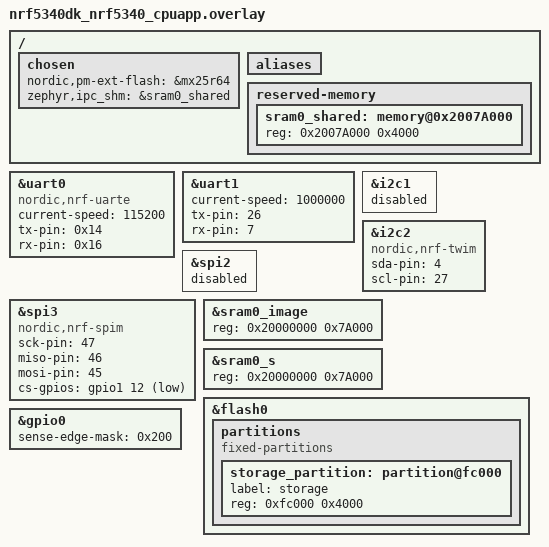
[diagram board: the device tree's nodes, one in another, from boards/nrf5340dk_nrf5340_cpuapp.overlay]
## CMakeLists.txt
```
# SPDX-License-Identifier: Apache-2.0

cmake_minimum_required(VERSION 3.13.1)

find_package(Zephyr REQUIRED HINTS $ENV{ZEPHYR_BASE})
project(comprensive_example)

# NORDIC SDK APP START

target_sources(app PRIVATE src/main.c)

target_sources_ifdef(CONFIG_EXAMPLE_I2C app
                     PRIVATE src/iic_thread.c)
					 
target_sources_ifdef(CONFIG_EXAMPLE_SPIM app
                     PRIVATE src/spi_thread.c)
					 
target_sources_ifdef(CONFIG_EXAMPLE_HS_UART app
                     PRIVATE src/uart_thread.c)
					 
target_sources_ifdef(CONFIG_EXAMPLE_ADC app
                     PRIVATE src/adc_thread.c)
					 
target_sources_ifdef(CONFIG_RPC_REMOTE_API app
                     PRIVATE src/rpc_app_api_general.c src/rpc_app_api.c src/rpc_thread.c)				 

target_sources_ifdef(CONFIG_RPC_SMP_BT app
                     PRIVATE src/rpc_app_smp_bt.c)
					 
target_sources_ifdef(CONFIG_EXAMPLE_FLASH app
                     PRIVATE src/flash_thread.c)

zephyr_library_include_directories(.)

# NORDIC SDK APP END
```

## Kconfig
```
#
# Copyright (c) 2018 Nordic Semiconductor ASA
#
# SPDX-License-Identifier: LicenseRef-BSD-5-Clause-Nordic
#

source "Kconfig.zephyr"
menu "comprehensive_rpc example"

config BLE_NETWORK_CORE
	bool "Both BLE host and controller run on network core"
	help
	  Enable the whole BLE stack running on network core

config EXAMPLE_I2C
	bool "load I2C example or not"
	help
		if yes, load I2C example
		
config EXAMPLE_SPIM
	bool "load SPI master example or not"
	help
		if yes, load SPI master example		
		
config EXAMPLE_EXT_INT
	bool "load external IO interrupt example or not"
	help
		if yes, load external IO interrupt example

config EXAMPLE_ADC
	bool "load ADC example or not"
	help
		if yes, load ADC example		

config EXAMPLE_HS_UART
	bool "load high speed UART example or not"
	help
		if yes, load high speed UART example	  

config EXAMPLE_FLASH
	bool "load Flash access usage example"
	default n
	help
		if yes, load Flash access usage example

config RPC_REMOTE_API
	bool "app core and net core communicate by remote API. that is, app core can call net core API, and net core can also call app core API"
	help
	  enable the RPC api mode
	  
config RPC_SMP_BT
	bool "load DFU example over BLE SMP"
	help
		if yes, load DFU example over BLE SMP		
		
module = COMPREHENSIVE_RPC_EXAMPLE_CONFIG
module-str = comprehensive_rpc example configurations
source "${ZEPHYR_BASE}/subsys/logging/Kconfig.template.log_config"

endmenu
```

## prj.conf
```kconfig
CONFIG_NFCT_PINS_AS_GPIOS=y

## thread monitor ##
CONFIG_THREAD_ANALYZER=y
CONFIG_THREAD_NAME=y

## logging configurations ##
CONFIG_ASSERT=y
CONFIG_LOG=y
CONFIG_LOG_PRINTK=y
CONFIG_LOG_BUFFER_SIZE=8192

## Change logging backend to RTT ##
# CONFIG_LOG_BACKEND_UART=n
# CONFIG_LOG_BACKEND_RTT=y
# CONFIG_USE_SEGGER_RTT=y
# CONFIG_RTT_CONSOLE=y
# CONFIG_UART_CONSOLE=n

## peripherals ##
CONFIG_GPIO=y
CONFIG_DK_LIBRARY=y

## stack size configurations ##
CONFIG_SYSTEM_WORKQUEUE_STACK_SIZE=4096
# CONFIG_ISR_STACK_SIZE=2048
CONFIG_HEAP_MEM_POOL_SIZE=12288
CONFIG_MAIN_STACK_SIZE=2048

## I2C master example ##
CONFIG_EXAMPLE_I2C=y
CONFIG_I2C=y
CONFIG_NRFX_TWIM2=y

## external interrupt example (in IIC thread) ##
CONFIG_EXAMPLE_EXT_INT=y

## high speed uart example ##
CONFIG_EXAMPLE_HS_UART=y
CONFIG_SERIAL=y
CONFIG_UART_ASYNC_API=y
CONFIG_UART_1_ASYNC=y
CONFIG_NRFX_UARTE1=y
CONFIG_UART_1_NRF_HW_ASYNC=y
CONFIG_UART_1_NRF_HW_ASYNC_TIMER=1

## SPI master example ##
CONFIG_EXAMPLE_SPIM=y
CONFIG_SPI=y
CONFIG_NRFX_SPIM3=y

## Load ADC example ##
CONFIG_EXAMPLE_ADC=y
CONFIG_ADC=y
CONFIG_ADC_ASYNC=y
CONFIG_ADC_NRFX_SAADC=y

## Flash access usage example ##
CONFIG_EXAMPLE_FLASH=y
CONFIG_FLASH=y
CONFIG_FLASH_PAGE_LAYOUT=y
CONFIG_FLASH_MAP=y
CONFIG_NVS=y
CONFIG_MPU_ALLOW_FLASH_WRITE=y
CONFIG_SETTINGS=y

## Device power management example ##
CONFIG_PM_DEVICE=y

## RPC example configurations ##
CONFIG_RPC_REMOTE_API=y
CONFIG_NRF_RPC=y
CONFIG_NRF_RPC_CBOR=y
CONFIG_NRF_RPC_THREAD_STACK_SIZE=4096

## Common DFU settings ##
CONFIG_BLE_NETWORK_CORE=y
CONFIG_NRF53_UPGRADE_NETWORK_CORE=y
CONFIG_BOOTLOADER_MCUBOOT=y
CONFIG_BOARD_ENABLE_CPUNET=y

## Open the following configs to run nrf_dfu ##
# CONFIG_NRF_DFU=y
# CONFIG_NRF_DFU_RPC_APP=y
# CONFIG_NRF_DFU_LOG_LEVEL=3
# CONFIG_IMG_MANAGER=y
# CONFIG_MCUBOOT_IMG_MANAGER=y
# CONFIG_IMG_BLOCK_BUF_SIZE=4096

## secondary slot on external Flash ##
CONFIG_PM_PARTITION_SIZE_SETTINGS_STORAGE=0x4000
CONFIG_NORDIC_QSPI_NOR=y
CONFIG_NORDIC_QSPI_NOR_FLASH_LAYOUT_PAGE_SIZE=4096
CONFIG_NORDIC_QSPI_NOR_STACK_WRITE_BUFFER_SIZE=16
CONFIG_STREAM_FLASH=y
CONFIG_STREAM_FLASH_ERASE=y

## Open the following configs to run SMP DFU ##
CONFIG_BOOTLOADER_MCUBOOT=y
CONFIG_MCUMGR=y
CONFIG_MCUMGR_CMD_IMG_MGMT=y
CONFIG_MCUMGR_CMD_OS_MGMT=y
CONFIG_OS_MGMT_TASKSTAT=n
CONFIG_OS_MGMT_ECHO=y
CONFIG_IMG_BLOCK_BUF_SIZE=2048
CONFIG_MCUMGR_BUF_COUNT=8
CONFIG_OS_MGMT_MCUMGR_PARAMS=y
# Enable the storage erase command.
CONFIG_MCUMGR_GRP_ZEPHYR_BASIC=y
CONFIG_MCUMGR_GRP_BASIC_CMD_STORAGE_ERASE=y

CONFIG_RPC_SMP_BT=y

## open the following configurations if you want to get a faster DFU speed
CONFIG_RPC_REASSEMBLY_BT=y
CONFIG_MCUMGR_BUF_SIZE=2475
CONFIG_MCUMGR_BUF_COUNT=4
```

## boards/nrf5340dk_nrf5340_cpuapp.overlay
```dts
/* overlay file for app core */

/* Open this config for NCS v1.8.0 or newer */
/ {
	chosen {
		nordic,pm-ext-flash = &mx25r64;
	};
};

&uart0 {
	compatible = "nordic,nrf-uarte";
	status = "okay";
	current-speed = < 115200 >;	
	tx-pin = < 0x14 >;
	rx-pin = < 0x16 >;
	/* delete rts-pin&cts-pin to release the related 2 pins for other uses */
	/delete-property/ rts-pin;
	/delete-property/ cts-pin;
};

&uart1 {
	status = "okay";
	current-speed = < 1000000 >;
	tx-pin = < 26 >;
	rx-pin = < 7 >;
};

&i2c1 {
	status = "disabled";
};

my_i2c: &i2c2 {
	status = "okay";
	compatible = "nordic,nrf-twim";
	sda-pin = <4>;
	scl-pin = <27>;
};

&spi2 {
	status = "disabled";
};

my_spi: &spi3 {
	status = "okay"; 
	compatible = "nordic,nrf-spim";
	sck-pin = < 47 >;
	miso-pin = < 46 >;
	mosi-pin = < 45 >;
	cs-gpios = <&gpio1 12 GPIO_ACTIVE_LOW>;
};

/* delete button4 to initialize the related pin for network core use */
/ {
 aliases {  
  /delete-property/ sw3;
 };
};

/delete-node/ &button3;

/* adjust the RAM size of application image */
&sram0_image{
	reg = < 0x20000000 0x7A000 >;
};

&sram0_s{
	reg = < 0x20000000 0x7A000 >;
};

/delete-node/ &sram0_shared;

/ {
	chosen {
		/* shared memory reserved for the inter-processor communication */
		zephyr,ipc_shm = &sram0_shared;
	};

	reserved-memory {
		#address-cells = <1>;
		#size-cells = <1>;
		ranges;	
		sram0_shared: memory@0x2007A000 {
			/* SRAM allocated to shared memory */
			reg = <0x2007A000 0x4000>;
		};
	};
};

/delete-node/ &storage_partition;
&flash0{
		partitions {
			compatible = "fixed-partitions";
			#address-cells = < 0x1 >;
			#size-cells = < 0x1 >;

			storage_partition: partition@fc000 {
				label = "storage";
				reg = < 0xfc000 0x4000 >;
			};
		};
};

&gpio0 {
	/* pin9 sense for edge */
	sense-edge-mask = <0x200>;
};
```

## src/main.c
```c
/*
 * Copyright (c) 2020 Nordic Semiconductor ASA
 *
 * SPDX-License-Identifier: LicenseRef-BSD-5-Clause-Nordic
 */

#include <zephyr.h>
#include <device.h>
#include <devicetree.h>
#include <drivers/gpio.h>
#include <stdio.h>
#include <dk_buttons_and_leds.h>
#include <nrf.h>
#include <nrfx.h>
#include <drivers/uart.h>
#ifdef CONFIG_MCUMGR_CMD_IMG_MGMT
#include "img_mgmt/img_mgmt.h"
#endif
#ifdef CONFIG_MCUMGR_CMD_OS_MGMT
#include "os_mgmt/os_mgmt.h"
#endif
#ifdef CONFIG_RPC_SMP_BT
#include "rpc_app_smp_bt.h"
#include <img_mgmt/img_mgmt_impl.h>
#endif
#ifdef CONFIG_NRF_DFU
#include "nrf_dfu_settings.h"
#include "nrf_dfu.h"
#include "sys/reboot.h"
#include "nrf_dfu.h"
#include "nrf_dfu_validation.h"
#endif
#include <logging/log.h>
#include <logging/log_ctrl.h>
#include <pm/device.h>

#define LOG_MODULE_NAME main
LOG_MODULE_REGISTER(LOG_MODULE_NAME);

#define ERASE_DELAY_AFTER_BOOT 30   //unit: s
static struct k_work_delayable blinky_work;

K_SEM_DEFINE(sem_rpc_tx, 0, 1);
K_SEM_DEFINE(sem_spi_txrx, 0, 1);

/* Stack definition for application workqueue */
K_THREAD_STACK_DEFINE(application_stack_area,
		      1024);
static struct k_work_q application_work_q;

/* The devicetree node identifier for the "led0" alias. */
#define LED0_NODE DT_ALIAS(led0)

#if DT_NODE_HAS_STATUS(LED0_NODE, okay)
#define LED0	DT_GPIO_LABEL(LED0_NODE, gpios)
#define LED0_PIN	DT_GPIO_PIN(LED0_NODE, gpios)
#define LED0_FLAGS	DT_GPIO_FLAGS(LED0_NODE, gpios)
#else
/* A build error here means your board isn't set up to blink an LED. */
#error "Unsupported board: led0 devicetree alias is not defined"
#define LED0	""
#define PIN	0
#define FLAGS	0
#endif

#ifdef CONFIG_PM_DEVICE
const struct device *devUart0;
const struct device *devUart1;
static void get_device_handles(void)
{
	devUart0 = device_get_binding("UART_0");
    devUart1 = device_get_binding("UART_1");
}

void set_device_pm_state(void)
{
	int err;
	enum pm_device_state pm_state;

	if (devUart1)
	{
		pm_device_state_get(devUart1, &pm_state);
		if (pm_state == PM_DEVICE_STATE_SUSPENDED)
		{
			LOG_INF("UART1 is in low power state. We activate it");
			err = pm_device_action_run(devUart1,PM_DEVICE_ACTION_RESUME);
			if (err) {
				LOG_ERR("UART1 enable failed");			
			}
			else
			{
				LOG_INF("## UART1 is active now ##");
			}		
		}
		else if (pm_state == PM_DEVICE_STATE_ACTIVE)
		{
			LOG_INF("UART1 is in active state. We suspend it");

#if CONFIG_UART_ASYNC_API && CONFIG_UART_1_NRF_HW_ASYNC
		((const struct uart_driver_api *)devUart1->api)->rx_disable(devUart1);
#endif			
			err = pm_device_action_run(devUart1,	PM_DEVICE_ACTION_SUSPEND);
			if (err) {
				LOG_ERR("UART1 disable failed");
			}
			else
			{
				LOG_INF("## UART1 is suspended now ##");
			}		
		}
	}

	pm_device_state_get(devUart0, &pm_state);
	if (pm_state == PM_DEVICE_STATE_SUSPENDED)
	{
		LOG_INF("UART0 is in low power state. We activate it");
		err = pm_device_action_run(devUart0,	PM_DEVICE_ACTION_RESUME);
		if (err) {
			LOG_ERR("UART0 enable failed");			
		}
		else
		{
			LOG_INF("## UART0 is active now ##");
		}		
	}
	else if (pm_state == PM_DEVICE_STATE_ACTIVE)
	{
		LOG_INF("UART0 is in active state. We suspend it");
		//print out all the pending logging messages
		while(log_process(false));

#if CONFIG_UART_ASYNC_API && CONFIG_UART_0_NRF_HW_ASYNC
		((const struct uart_driver_api *)devUart0->api)->rx_disable(devUart0);
#endif
		err = pm_device_action_run(devUart0,	PM_DEVICE_ACTION_SUSPEND);
		if (err) {
			LOG_ERR("UART0 disable failed");
		}
		else
		{
			LOG_INF("## UART0 is suspended now ##");
		}		
	}

}

#endif //CONFIG_PM_DEVICE

void button_changed(uint32_t button_state, uint32_t has_changed)
{
	uint32_t buttons = button_state & has_changed;
	
	if (buttons & DK_BTN1_MSK) {
		LOG_INF("button1 isr");
		k_sem_give(&sem_rpc_tx);		
	}

	if (buttons & DK_BTN2_MSK) {
		LOG_INF("button2 isr");
		k_sem_give(&sem_spi_txrx);
	}

	if (buttons & DK_BTN3_MSK) {
		LOG_INF("button3 isr");
#ifdef CONFIG_PM_DEVICE		
		set_device_pm_state();
#endif		
	}			
}

const struct device *ledDev;
bool led_is_on = true;

static void blinky_work_fn(struct k_work *work)
{
    //printk("blinky fn in system workqueue\n");
	gpio_pin_set(ledDev, LED0_PIN, (int)led_is_on);
	led_is_on = !led_is_on;

	k_work_reschedule_for_queue(&application_work_q, &blinky_work,
					   	K_SECONDS(2));

}

static void assign_io_to_netcore(void)
{
	NRF_P0_S->PIN_CNF[9] = (GPIO_PIN_CNF_MCUSEL_NetworkMCU <<
					GPIO_PIN_CNF_MCUSEL_Pos);
}

#ifdef CONFIG_NRF_DFU
/**@brief Function for handling DFU events.
 */
static void dfu_observer(nrf_dfu_evt_type_t evt_type)
{
    switch (evt_type)
    {
        case NRF_DFU_EVT_DFU_STARTED:
        case NRF_DFU_EVT_OBJECT_RECEIVED:

            break;
        case NRF_DFU_EVT_DFU_COMPLETED:
        case NRF_DFU_EVT_DFU_ABORTED:
			LOG_INF("resetting...");
			while(log_process(false));
            sys_reboot(SYS_REBOOT_WARM);
            break;
        case NRF_DFU_EVT_TRANSPORT_DEACTIVATED:
            // Reset the internal state of the DFU settings to the last stored state.
			LOG_INF("NRF_DFU_EVT_TRANSPORT_DEACTIVATED");
            nrf_dfu_settings_reinit();
            break;
        default:
            break;
    }

}

int dfu_init(void)
{
    int ret_val;

    ret_val = nrf_dfu_settings_init(true);
    if (ret_val != NRF_SUCCESS)
	{
		LOG_WRN("dfu settings init err %d", ret_val);
	}

    ret_val = nrf_dfu_init(dfu_observer);
    if (ret_val != NRF_SUCCESS)
	{
		LOG_WRN("dfu init err %d", ret_val);
	}

    return ret_val;
}
#endif //CONFIG_NRF_DFU

void main(void)
{
	int err;	

	LOG_INF("### comprehensive example @ appcore version v0.2 compiled at %s %s\n", __TIME__, __DATE__);
	assign_io_to_netcore();

	ledDev = device_get_binding(LED0);
	if (ledDev == NULL) {
		return;
	}

#ifdef CONFIG_PM_DEVICE
	get_device_handles();
#endif

	err = gpio_pin_configure(ledDev, LED0_PIN, GPIO_OUTPUT_ACTIVE | LED0_FLAGS);
	if (err < 0) {
		printk("gpio configure error %d \n", err);
		return;
	}

	err = dk_buttons_init(button_changed);
	if (err) {
		printk("Cannot init buttons (err: %d)", err);
	}

	k_work_queue_start(&application_work_q, application_stack_area,
			   K_THREAD_STACK_SIZEOF(application_stack_area), 10,
			   NULL);
	k_work_init_delayable(&blinky_work, blinky_work_fn);
	k_work_reschedule_for_queue(&application_work_q, &blinky_work,
					   	K_MSEC(20));	

#ifdef CONFIG_RPC_SMP_BT
	LOG_INF("## OTA/Serial DFU example ##");	
#ifdef CONFIG_MCUMGR_CMD_OS_MGMT
	os_mgmt_register_group();
#endif	
#ifdef CONFIG_MCUMGR_CMD_IMG_MGMT
	img_mgmt_register_group();
#endif //CONFIG_MCUMGR_CMD_IMG_MGMT
#endif  //CONFIG_RPC_SMP_BT

#ifdef CONFIG_NRF_DFU
	err = dfu_init();
	if (err) {
		LOG_ERR("dfu service init err %d", err);		
	}
#endif //CONFIG_NRF_DFU
	//main thread 
	while(1)
	{
		//add your code here
		k_sleep(K_SECONDS(20));
		LOG_INF("main thread\n");
	}
	//since we don't put any work in main thread, exit directly
	LOG_WRN("exit main thread\n");
}
```

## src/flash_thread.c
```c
/*
 * Copyright (c) 2020 Nordic Semiconductor ASA
 *
 * SPDX-License-Identifier: LicenseRef-BSD-5-Clause-Nordic
 */

#include <zephyr.h>
#include <device.h>
#include <string.h>
#include <drivers/flash.h>
#include <storage/flash_map.h>
#include <fs/nvs.h>
#include "settings/settings.h"
#include <logging/log.h>

#define LOG_MODULE_NAME flash_thread
LOG_MODULE_REGISTER(LOG_MODULE_NAME);

static struct nvs_fs fs;

#define KEY_ID 1
#define RBT_CNT_ID 2

int nvs_usage_init(void)
{
	int rc;
	uint8_t key[8];
	uint32_t reboot_counter = 0U;
	const struct device *flash_dev;
	struct flash_pages_info info;

	flash_dev = device_get_binding(DT_CHOSEN_ZEPHYR_FLASH_CONTROLLER_LABEL);
	if (!device_is_ready(flash_dev)) {
		LOG_ERR("Flash device %s is not ready", flash_dev->name);
		return -EINVAL;
	}
	fs.offset = FLASH_AREA_OFFSET(storage);
	rc = flash_get_page_info_by_offs(flash_dev, fs.offset, &info);
	if (rc) {
		LOG_ERR("Unable to get page info");
		return -EINVAL;
	}
	fs.sector_size = info.size;
	fs.sector_count = CONFIG_PM_PARTITION_SIZE_SETTINGS_STORAGE / info.size;

	LOG_INF("NVS sector size=%d sector count=%d\n", fs.sector_size, fs.sector_count);

	rc = nvs_init(&fs, DT_CHOSEN_ZEPHYR_FLASH_CONTROLLER_LABEL);
	if (rc)
	{
		LOG_ERR("Flash Init failed %d", rc);
		return -EINVAL;
	}

	/* KEY_ID is used to store a key, lets see if we can read it from flash
	 */
	rc = nvs_read(&fs, KEY_ID, &key, sizeof(key));
	if (rc > 0)
	{ /* item was found, show it */
		LOG_HEXDUMP_INF(key, sizeof(key), "Key value in NVS:");
	}
	else
	{ /* item was not found, add it */
		LOG_INF("No key found, adding it at id %d by NVS API", KEY_ID);
		key[0] = 0xFF;
		key[1] = 0xFE;
		key[2] = 0xFD;
		key[3] = 0xFC;
		key[4] = 0xFB;
		key[5] = 0xFA;
		key[6] = 0xF9;
		key[7] = 0xF8;
		(void)nvs_write(&fs, KEY_ID, &key, sizeof(key));
	}
	/* RBT_CNT_ID is used to store the reboot counter, lets see
	 * if we can read it from flash
	 */
	reboot_counter = 0;
	rc = nvs_read(&fs, RBT_CNT_ID, &reboot_counter, sizeof(reboot_counter));
	if (rc > 0)
	{ /* item was found, show it */
		LOG_INF("*** Reboot counter in NVS: %d ***",
				reboot_counter);
	}
	LOG_INF("save new reboot counter by NVS API");
	reboot_counter++;
	(void)nvs_write(&fs, RBT_CNT_ID, &reboot_counter,
					sizeof(reboot_counter));

	return 0;
}

static uint32_t reboot_cnt;
static uint8_t key_s[8];

int alpha_handle_set(const char *name, size_t len, settings_read_cb read_cb,
					 void *cb_arg)
{
	const char *next;
	int rc;

	LOG_INF("set handler name=%s, len=%d ", log_strdup(name), len);
	if (settings_name_steq(name, "boot_cnt", &next) && !next)
	{
		if (len != sizeof(reboot_cnt))
		{
			return -EINVAL;
		}
		rc = read_cb(cb_arg, &reboot_cnt, sizeof(reboot_cnt));
		LOG_INF("*** Reboot counter in Settings: %d ****", reboot_cnt);
		return 0;
	}

	if (settings_name_steq(name, "key", &next) && !next)
	{
		if (len != sizeof(key_s))
		{
			return -EINVAL;
		}
		rc = read_cb(cb_arg, key_s, sizeof(key_s));
		LOG_HEXDUMP_INF(key_s, sizeof(key_s), "Key value in Settings:");
		return 0;
	}

	return -ENOENT;
}

/* dynamic main tree handler */
struct settings_handler alph_handler = {
	.name = "alpha",
	.h_get = NULL,
	.h_set = alpha_handle_set,
	.h_commit = NULL,
	.h_export = NULL};

void settings_usage_init(void)
{
	int rc;

	rc = settings_subsys_init();
	if (rc)
	{
		LOG_ERR("settings subsys initialization: fail (err %d) ", rc);
		return;
	}

	LOG_INF("settings subsys initialization: OK.");

	rc = settings_register(&alph_handler);
	if (rc)
	{
		LOG_ERR("subtree <%s> handler registered: fail (err %d)",
				alph_handler.name, rc);
	}

	/* load all key-values at once
	 * In case a key-value doesn't exist in the storage
	 * default valuse should be assigned to settings variable
	 * before any settings load call
	 */
	LOG_INF("Load all key-value pairs using registered handlers");
	settings_load();

	if (reboot_cnt == 0)
	{
		LOG_INF("save key_s By Settings API");
		key_s[0] = 0x30;
		key_s[1] = 0x31;
		key_s[2] = 0x32;
		key_s[3] = 0x33;
		key_s[4] = 0x34;
		key_s[5] = 0x35;
		key_s[6] = 0x36;
		key_s[7] = 0x37;
		rc = settings_save_one("alpha/key", (const void *)key_s,
							   sizeof(key_s));
		if (rc)
		{
			LOG_ERR("key_s save err %d ", rc);
		}
	}

	LOG_INF("save new reboot counter by Settings API");
	reboot_cnt++;
	rc = settings_save_one("alpha/boot_cnt", (const void *)&reboot_cnt,
						   sizeof(reboot_cnt));
	if (rc)
	{
		LOG_ERR("boot_cnt save err %d ", rc);
	}
}
void flash_thread(void)
{

	LOG_INF("**Flash access example using both NVS and settings API");

	nvs_usage_init();

	settings_usage_init();

	while (1)
	{
		LOG_INF("Flash thread");
		k_sleep(K_SECONDS(20));
	}
}

K_THREAD_DEFINE(flash_thread_id, 1024, flash_thread, NULL, NULL,
				NULL, 9, 0, 0);
```

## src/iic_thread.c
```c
/*
 * Copyright (c) 2020 Nordic Semiconductor ASA
 *
 * SPDX-License-Identifier: LicenseRef-BSD-5-Clause-Nordic
 */

#include <zephyr.h>
#include <device.h>
#include <devicetree.h>
#include <drivers/gpio.h>
#include <drivers/i2c.h>
#include <logging/log.h>

#define LOG_MODULE_NAME i2c_thread
LOG_MODULE_REGISTER(LOG_MODULE_NAME);

const struct device *i2c_dev;
const static struct device *gpio_dev;
//static struct k_delayed_work read_eeprom;
K_SEM_DEFINE(sem_iic_op, 0, 1);

#define EXT_INT_IO	6  //p0.06
#define EXT_INT_CONF	(GPIO_INPUT | GPIO_PULL_UP)

static struct gpio_callback ext_int_cb_data;

#define EEPROM_SIM_SIZE                   (320u) //!< Simulated EEPROM size.

#define EEPROM_SIM_ADDR                   0x50    //!< Simulated EEPROM TWI slave address.

/* Slave memory addressing byte length */
#define EEPROM_SIM_ADDRESS_LEN_BYTES    2

#define IN_LINE_PRINT_CNT   (16u)   //!< Number of data bytes printed in a single line.


static int eeprom_read(uint16_t addr, uint8_t * pdata, size_t size)
{
    int ret;
    if (size > (EEPROM_SIM_SIZE))
    {
        return EINVAL;
    }
    do
    {
       uint16_t addr16 = addr;
       ret = i2c_write(i2c_dev, (uint8_t *)&addr16, EEPROM_SIM_ADDRESS_LEN_BYTES, EEPROM_SIM_ADDR);
       if (0 != ret)
       {
           break;
       }
       ret = i2c_read(i2c_dev, pdata, size, EEPROM_SIM_ADDR);
    }while (0);
    return ret;
}

static void eeprom_cmd_read(void)
{    
    uint8_t buf[IN_LINE_PRINT_CNT+1];

    for (uint16_t addr = 0; addr < EEPROM_SIM_SIZE; addr += IN_LINE_PRINT_CNT)
    {
        int err_code;
        err_code = eeprom_read(addr, buf, IN_LINE_PRINT_CNT);
        buf[IN_LINE_PRINT_CNT] = '\0';
        if (0 != err_code)
        {
            LOG_ERR("EEPROM transmission error %d\n", err_code);
            return;
        }

        LOG_HEXDUMP_INF(buf, IN_LINE_PRINT_CNT, "EEPROM: ");        
      
    }
}

// static void eeprom_read_fn(struct k_work *work)
// {
//     printk("eeprom read in system workqueue\n");
// 	eeprom_cmd_read();
//     k_delayed_work_submit(&read_eeprom, K_SECONDS(2));
// }

void ext_int_isr(const struct device *dev, struct gpio_callback *cb,
		    uint32_t pins)
{
	LOG_INF("external interrupt occurs at %x", pins);   
    k_sem_give(&sem_iic_op);    
}

#ifdef CONFIG_EXAMPLE_EXT_INT
void config_io_interrupt(void)
{
	int ret;

	gpio_dev = device_get_binding(DT_LABEL(DT_NODELABEL(gpio0)));
	if (!gpio_dev) {
		LOG_ERR("Error: didn't find GPIO_0\n");
		return;
	}

	ret = gpio_pin_configure(gpio_dev, EXT_INT_IO, EXT_INT_CONF);
	if (ret != 0) {
		LOG_ERR("Error %d: failed to configure pin %d\n",
		       ret, EXT_INT_IO);
	}

	ret = gpio_pin_interrupt_configure(gpio_dev,
					   EXT_INT_IO,
					   GPIO_INT_EDGE_FALLING);
	if (ret != 0) {
		LOG_ERR("Error %d: failed to configure interrupt on pin %d\n",
			ret, EXT_INT_IO);
	}

	gpio_init_callback(&ext_int_cb_data, ext_int_isr, BIT(EXT_INT_IO));
	gpio_add_callback(gpio_dev, &ext_int_cb_data);
	LOG_INF("**External interrupt example at P0.%d\n", EXT_INT_IO);
}
#endif //CONFIG_EXAMPLE_EXT_INT

void iic_thread(void)
{
	
	LOG_INF("** I2C master example **");
	LOG_INF("This example is ported from nRF5_SDK\\examples\\peripheral\\twi_master_with_twis_slave");
	LOG_INF("The related twis example is from nRF5_SDK\\examples\\peripheral\\twi_master_with_twis_slave");	
	
	i2c_dev = device_get_binding(DT_LABEL(DT_NODELABEL(my_i2c)));
	if (!i2c_dev) {
		LOG_ERR("I2C Device driver not found");
		return;
	}
    uint32_t i2c_cfg = I2C_SPEED_SET(I2C_SPEED_FAST) | I2C_MODE_MASTER;
    if (i2c_configure(i2c_dev, i2c_cfg)) {
        LOG_ERR("I2C config failed");
        return;
    }
#ifdef CONFIG_EXAMPLE_EXT_INT
    config_io_interrupt();    
#endif
    
	// k_delayed_work_init(&read_eeprom, eeprom_read_fn);
    // k_delayed_work_submit(&read_eeprom, K_MSEC(50));	    

	while (1) {        
        k_sem_take(&sem_iic_op, K_FOREVER);
        LOG_INF("i2c master thread");
        eeprom_cmd_read();
        k_sleep(K_SECONDS(2));
	}
}

K_THREAD_DEFINE(iic_thread_id, 1024, iic_thread, NULL, NULL,
		NULL, 7, 0, 0);
```

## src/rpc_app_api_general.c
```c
/*
 * Copyright (c) 2020 Nordic Semiconductor ASA
 *
 * SPDX-License-Identifier: LicenseRef-BSD-5-Clause-Nordic
 */
#include <errno.h>
#include <zephyr/init.h>
#include <string.h>
#include <nrf_rpc_cbor.h>
#include <zcbor_common.h>
#include <zcbor_decode.h>
#include <zcbor_encode.h>
#include "common_ids.h"
#include <logging/log.h>
#include "rpc_app_api.h"

#define LOG_MODULE_NAME rpc_app_api_general
LOG_MODULE_REGISTER(LOG_MODULE_NAME);


#define CBOR_BUF_SIZE 16


NRF_RPC_GROUP_DEFINE(rpc_api, "rpc_api", NULL, NULL, NULL);

static void rsp_error_code_handle(struct nrf_rpc_cbor_ctx *ctx, void *handler_data)
{
	int32_t val;

	if (zcbor_int32_decode(ctx->zs, &val)) {
		*(int *)handler_data = (int)val;
	} else {
		*(int *)handler_data = -NRF_EINVAL;
	}
}

static void rsp_error_code_send(int err_code)
{
	struct nrf_rpc_cbor_ctx ctx;

	NRF_RPC_CBOR_ALLOC(ctx, CBOR_BUF_SIZE);
	zcbor_int32_put(ctx.zs, err_code);

	nrf_rpc_cbor_rsp_no_err(&ctx);
}

int rpc_app2net_send(int32_t type, uint8_t *buffer, int32_t length)
{
	int err;
	int32_t result = 0;
	struct nrf_rpc_cbor_ctx ctx;

	printk("buf:%p, len:%d \r", buffer, length);
	if (!buffer || length < 1) {
		return -NRF_EINVAL;
	}	

	NRF_RPC_CBOR_ALLOC(ctx, CBOR_BUF_SIZE + length);
	
	zcbor_int32_put(ctx.zs, type);
	zcbor_int32_put(ctx.zs, length);
	zcbor_bstr_encode_ptr(ctx.zs, buffer, length);	

	err = nrf_rpc_cbor_cmd(&rpc_api, RPC_COMMAND_APP_SEND, &ctx,
			       rsp_error_code_handle, &result);
	printk("err %d result %d\r", err, result);
	if (err) {
		return err;
	}

	return result;
}

static void rpc_net2app_send(struct nrf_rpc_cbor_ctx *ctx, void *handler_data)
{	
	struct zcbor_string zst;
	int err_code = -NRF_EINVAL;
	size_t length;
	uint8_t buf[256];
	int type;
	

	if (!zcbor_int32_decode(ctx->zs, &type)) {
		goto cbor_error_exit;
	}

	if (!zcbor_int32_decode(ctx->zs, &length) || length > ARRAY_SIZE(buf)) {
		goto cbor_error_exit;
	}
	
	if (!zcbor_bstr_decode(ctx->zs, &zst) || zst.len != length) {
		goto cbor_error_exit;
	}
	memcpy(buf, zst.value, zst.len);
	err_code = net2app_receive(type, buf, length);

cbor_error_exit:
	nrf_rpc_cbor_decoding_done(ctx);
	rsp_error_code_send(err_code);
}


NRF_RPC_CBOR_CMD_DECODER(rpc_api, rpc_net2app_send_name,
			 RPC_COMMAND_NET_SEND,
			 rpc_net2app_send, NULL);


static void err_handler(const struct nrf_rpc_err_report *report)
{
	printk("nRF RPC error %d ocurred. See nRF RPC logs for more details.",
	       report->code);
	k_oops();
}


static int serialization_init(const struct device *dev)
{
	ARG_UNUSED(dev);

	int err;

	printk("Init begin\n");

	err = nrf_rpc_init(err_handler);
	if (err) {
		return -NRF_EINVAL;
	}

	printk("Init done\n");

	return 0;
}


SYS_INIT(serialization_init, POST_KERNEL, CONFIG_APPLICATION_INIT_PRIORITY);
```

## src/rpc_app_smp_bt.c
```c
/*
 * Copyright (c) 2020 Nordic Semiconductor ASA
 *
 * SPDX-License-Identifier: LicenseRef-BSD-5-Clause-Nordic
 */
#include <errno.h>
#include <init.h>
#include <nrf_rpc_cbor.h>
#include <zcbor_common.h>
#include <zcbor_decode.h>
#include <zcbor_encode.h>
#include "common_ids.h"
#include <mgmt/mcumgr/buf.h>
#include <mgmt/mcumgr/smp.h>
#include <net/buf.h>
#include <logging/log.h>

LOG_MODULE_REGISTER(rpc_app_smp, 3);

#define CBOR_BUF_SIZE 16
static struct zephyr_smp_transport smp_rpc_transport;

NRF_RPC_GROUP_DEFINE(rpc_smp, "rpc_smp", NULL, NULL, NULL);

static void rsp_error_code_send(int err_code)
{
	struct nrf_rpc_cbor_ctx ctx;

	NRF_RPC_CBOR_ALLOC(ctx, CBOR_BUF_SIZE);
	zcbor_int32_put(ctx.zs, err_code);

	nrf_rpc_cbor_rsp_no_err(&ctx);
}

static int smp_receive_data(const void *buf, uint16_t len)
{
	struct net_buf *nb;

	LOG_HEXDUMP_DBG(buf, len, "rpc app smp rx:");
	nb = mcumgr_buf_alloc();
	if (!nb)
	{
		LOG_ERR("net buf alloc failed");
		return -ENOMEM;
	}
	net_buf_add_mem(nb, buf, len);
	zephyr_smp_rx_req(&smp_rpc_transport, nb);	

	return 0;
}

static void rpc_app_bt_smp_receive_cb(struct nrf_rpc_cbor_ctx *ctx, void *handler_data)
{	
	struct zcbor_string zst;
	int err;	
	uint8_t buf[270];

	LOG_INF("rpc rx data");
	if (!zcbor_bstr_decode(ctx->zs, &zst) || zst.len > sizeof(buf)) {
		err = -NRF_EBADMSG;
		LOG_ERR("cbor decode err in smp rx");		
	}
	else
	{	
		memcpy(buf, zst.value, zst.len);	
		err = smp_receive_data(buf, zst.len);
	}

	nrf_rpc_cbor_decoding_done(ctx);

	rsp_error_code_send(err);
}

NRF_RPC_CBOR_CMD_DECODER(rpc_smp, rpc_app_bt_smp_receive,
			 RPC_COMMAND_NET_BT_SMP_RECEIVE_CB,
			 rpc_app_bt_smp_receive_cb, NULL);


static void rsp_error_code_handle(struct nrf_rpc_cbor_ctx *ctx, void *handler_data)
{
	int32_t val;

	if (zcbor_int32_decode(ctx->zs, &val)) {
		*(int *)handler_data = (int)val;
	} else {
		*(int *)handler_data = -NRF_EINVAL;
	}
}

int rpc_app_bt_smp_send(uint8_t *buffer, uint16_t length)
{
	int err;
	int result;
	struct nrf_rpc_cbor_ctx ctx;

	if (!buffer || length < 1) {
		LOG_ERR("rpc app send err");
		return -NRF_EINVAL;
	}	

	NRF_RPC_CBOR_ALLOC(ctx, CBOR_BUF_SIZE + length);
	
	zcbor_bstr_encode_ptr(ctx.zs, buffer, length);	

	err = nrf_rpc_cbor_cmd(&rpc_smp, RPC_COMMAND_APP_BT_SMP_SEND, &ctx,
			       rsp_error_code_handle, &result);
	if (err) {
		return err;
	}

	return result;
}
/**
 * Transmits the specified SMP response.
 */
static int smp_rpc_tx_pkt(struct zephyr_smp_transport *zst, struct net_buf *nb)
{	
	int rc;
	LOG_HEXDUMP_INF(nb->data, nb->len, "rpc app send");
	rc = rpc_app_bt_smp_send(nb->data, nb->len);
	mcumgr_buf_free(nb);
	return rc;
}

int rpc_app_bt_smp_get_mtu(void)
{
	int err;
	int result;
	struct nrf_rpc_cbor_ctx ctx;

	NRF_RPC_CBOR_ALLOC(ctx, CBOR_BUF_SIZE);

	err = nrf_rpc_cbor_cmd(&rpc_smp, RPC_COMMAND_APP_BT_SMP_GET_MTU, &ctx,
			       rsp_error_code_handle, &result);
	if (err < 0) {
		return err;
	}

	return result;
}

static uint16_t smp_rpc_get_mtu(const struct net_buf *nb)
{
	int mtu = rpc_app_bt_smp_get_mtu();
	return mtu < 0 ? 0: mtu;     
}

int smp_rpc_init(const struct device *dev)
{	
	ARG_UNUSED(dev);
	
	zephyr_smp_transport_init(&smp_rpc_transport, smp_rpc_tx_pkt,
				  smp_rpc_get_mtu, NULL,
				  NULL);
	return 0;
}

SYS_INIT(smp_rpc_init, APPLICATION, CONFIG_APPLICATION_INIT_PRIORITY);
```

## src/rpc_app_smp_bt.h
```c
/*
 * Copyright (c) 2020 Nordic Semiconductor ASA
 *
 * SPDX-License-Identifier: Apache-2.0
 */

#ifndef RPC_APP_SMP_BT_H_
#define RPC_APP_SMP_BT_H_

#include <zephyr/types.h>

/**
 * @file
 * @defgroup entropy_ser Entropy driver serialization
 * @{
 * @brief Entropy serialization API.
 */

#ifdef __cplusplus
extern "C" {
#endif

int smp_rpc_init(void);

#ifdef __cplusplus
}
#endif

/**
 * @}
 */

#endif /* RPC_APP_SMP_BT_H_ */
```

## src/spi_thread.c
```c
/*
 * Copyright (c) 2020 Nordic Semiconductor ASA
 *
 * SPDX-License-Identifier: LicenseRef-BSD-5-Clause-Nordic
 */

#include <zephyr.h>
#include <device.h>
#include <devicetree.h>
#include <drivers/gpio.h>
#include <logging/log.h>
#include <drivers/spi.h>

#define LOG_MODULE_NAME spi_thread
LOG_MODULE_REGISTER(LOG_MODULE_NAME);

#define SPI_DEVICE_NAME         "SPI_3"
#define PIN_SPIM_CS	12  //P1.12
#define DELAY_SPI_CS_ACTIVE_US 2
#define TEST_STRING "Nordic"

const struct device *spi_dev;
extern struct k_sem sem_spi_txrx;

static int spi_data_exchange(void)
{
    int err;
    struct spi_cs_control cs_ctrl;
    struct spi_config spi_cfg = {0};

	spi_cfg.frequency = 8000000U;
	spi_cfg.operation = SPI_WORD_SET(8);	

	cs_ctrl.gpio_dev =
		device_get_binding("GPIO_1");
	if (!cs_ctrl.gpio_dev) {
        LOG_ERR("cannot find GPIO_1 device");
		return -ENODEV;
	}

	cs_ctrl.gpio_pin = PIN_SPIM_CS;
	cs_ctrl.gpio_dt_flags = GPIO_ACTIVE_LOW;
	cs_ctrl.delay = DELAY_SPI_CS_ACTIVE_US;

	spi_cfg.cs = &cs_ctrl;

	uint8_t buf[] = TEST_STRING;
    uint8_t data[] = TEST_STRING;

	struct spi_buf spi_buf[2] = {
		{
			.buf = buf,
			.len = sizeof(buf),
		},
		{
			.buf = data,
			.len = sizeof(data)
		}
	};
    
	const struct spi_buf_set tx_set = {
		.buffers = spi_buf,
		.count = 1
	};

	const struct spi_buf_set rx_set = {
		.buffers = spi_buf,
		.count = 1
	};

	// const struct spi_buf_set tx_set = {
	// 	.buffers = spi_buf,
	// 	.count = 2
	// };

	// const struct spi_buf_set rx_set = {
	// 	.buffers = spi_buf,
	// 	.count = 2
	// };    

	err = spi_transceive(spi_dev, &spi_cfg, &tx_set, &rx_set);
    
    if (err)
    {
        LOG_ERR("SPI transcation failed err %d", err);
    }
    else
    {
        LOG_HEXDUMP_INF(rx_set.buffers->buf, rx_set.buffers->len, "Received SPI data: ");
    }

    return err;

}

void spi_thread(void)
{	
	
	LOG_INF("** SPI master example **");
	LOG_INF("This example is ported from nRF5_SDK\\examples\\peripheral\\spi");
	LOG_INF("The related spis example is from nRF5_SDK\\examples\\peripheral\\spis");	

	spi_dev = device_get_binding(SPI_DEVICE_NAME);
	if (!spi_dev) {
		LOG_ERR("SPIM driver not found.\n");
		return;
	}
    k_sem_take(&sem_spi_txrx, K_FOREVER);
	while (1) {                
        LOG_INF("spi master thread");
        spi_data_exchange();
        k_sleep(K_MSEC(200)); 
	}
}

K_THREAD_DEFINE(spi_thread_id, 1024, spi_thread, NULL, NULL,
		NULL, 7, 0, 0);
```

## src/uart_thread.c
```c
/*
 * Copyright (c) 2020 Nordic Semiconductor ASA
 *
 * SPDX-License-Identifier: LicenseRef-BSD-5-Clause-Nordic
 */

#include <zephyr.h>
#include <device.h>
#include <devicetree.h>
#include <drivers/gpio.h>
#include <stdio.h>
#include <logging/log.h>
#include <drivers/uart.h>
#include <drivers/gpio.h>
#include "nrf_rpc_tr.h"
#include "rpc_app_api.h"

#define LOG_MODULE_NAME uart_thread
LOG_MODULE_REGISTER(LOG_MODULE_NAME);

#define MY_UARTE			DT_NODELABEL(uart1)
#define UART_DEVICE_NAME         DT_LABEL(MY_UARTE)

#define UART_BUF_SIZE 255
#define UART_WAIT_FOR_BUF_DELAY K_MSEC(100)
#define UART_WAIT_FOR_RX 10000

static const struct device *uart;

struct uart_data_t {
	void *fifo_reserved;
	uint8_t data[UART_BUF_SIZE];
	uint16_t len;
};

static uint8_t uart_rx_buf[2][UART_BUF_SIZE];
static uint8_t *next_buf = uart_rx_buf[1];

static K_FIFO_DEFINE(fifo_uart_tx_data);
static K_FIFO_DEFINE(fifo_uart_rx_data);


static void uart_cb(const struct device *dev, struct uart_event *evt, void *user_data)
{
	ARG_UNUSED(dev);
	int err;

	switch (evt->type) {
	case UART_TX_DONE:
	{
		struct uart_data_t *buf;
		struct uart_data_t *buf2;
		
		buf = CONTAINER_OF(evt->data.tx.buf, struct uart_data_t,  data);		
		LOG_INF("UART_TX_DONE %d", evt->data.tx.len);
		k_free(buf);

		buf2 = k_fifo_get(&fifo_uart_tx_data, K_NO_WAIT);
		if (!buf2) {
			return;
		}

		if (uart_tx(uart, buf2->data, buf2->len, SYS_FOREVER_MS)) {
			LOG_WRN("uart_tx fail @ cb");
		}
	}
		break;

	case UART_RX_RDY:
	{
		struct uart_data_t *buf = k_malloc(sizeof(struct uart_data_t));
		memcpy(buf->data, &evt->data.rx.buf[evt->data.rx.offset], evt->data.rx.len);	
		buf->len = evt->data.rx.len;		
		k_fifo_put(&fifo_uart_rx_data, buf);
		LOG_INF("UART_RX_RDY %d", buf->len);
	}
		break;

	case UART_RX_DISABLED:
		LOG_INF("UART_RX_DISABLED");
		err = uart_rx_enable(uart, uart_rx_buf[0], sizeof(uart_rx_buf[0]), UART_WAIT_FOR_RX);
		if (err) {
			LOG_ERR("UART RX enable failed: %d", err);			
		}
		break;

	case UART_RX_BUF_REQUEST:
		err = uart_rx_buf_rsp(uart, next_buf,
			sizeof(uart_rx_buf[0]));
		if (err) {
			LOG_WRN("UART RX buf rsp: %d", err);
		}		
		break;

	case UART_RX_BUF_RELEASED:
		LOG_INF("UART_RX_BUF_RELEASED");
		next_buf = evt->data.rx_buf.buf;
		break;

	case UART_TX_ABORTED:
		LOG_INF("UART_TX_ABORTED");
		break;

	default:
		break;
	}
}

static int uart_init(void)
{
	int err;
	
	uart = device_get_binding(UART_DEVICE_NAME);
	if (!uart) {
		return -ENXIO;
	}

	err = uart_callback_set(uart, uart_cb, NULL);
	if (err) {
		return err;
	}

	return uart_rx_enable(uart, uart_rx_buf[0], sizeof(uart_rx_buf[0]), UART_WAIT_FOR_RX);

}

int my_uart_send(const uint8_t *buf, size_t len)
{
	int err;
	struct uart_data_t *tx = k_malloc(sizeof(*tx));

	if (!tx) {
		LOG_WRN("Not able to allocate UART send data buffer");
		return -ENOMEM; 
	}

	memcpy(tx->data, buf, len);	
	tx->len = len;
	err = uart_tx(uart, tx->data, tx->len, SYS_FOREVER_MS);
	if (err) {
		LOG_WRN("buffer uart tx data for later retry");
		k_fifo_put(&fifo_uart_tx_data, tx);
	}
	return err;		
}

void uart_thread(void)
{    
	static uint32_t uart_len;

	LOG_INF("**high speed UART example");

	uart_init();

	while (1) {

		/* Send the UART data back to the peer. Wait indefinitely*/
		struct uart_data_t *buf = k_fifo_get(&fifo_uart_rx_data,
						     K_FOREVER);
#ifdef CONFIG_RPC_REMOTE_API
		if (is_ble_connected())
		{
			int err = app2net_send_nus(buf->data,buf->len);
			if (err) {
				LOG_WRN("app2net_send_nus err %d", err);			
			}	
		}
#endif

		my_uart_send(buf->data,buf->len);
		
		LOG_HEXDUMP_INF(buf->data, buf->len, "uart received:");
		k_free(buf);					
	}
}

K_THREAD_DEFINE(uart_thread_id, 1024, uart_thread, NULL, NULL,
		NULL, 5, 0, 0);
```
